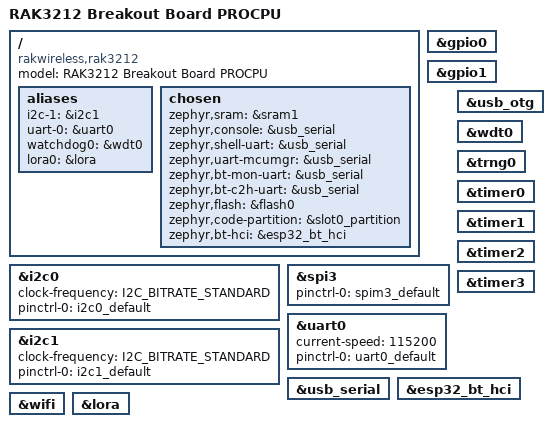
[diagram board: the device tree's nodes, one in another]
/*
 * Copyright (c) 2025 Kenneth Lu <kenneth.lu@rakwireless.com>
 * Copyright (c) 2026 JaeHwan Jin <jaehwan.jin@rakwireless.com>
 * SPDX-License-Identifier: Apache-2.0
 */

/dts-v1/;
#include <rakwireless/rak3112_procpu.dtsi>
#include <espressif/partitions_0x0_amp_16M.dtsi>
#include "rak3212-pinctrl.dtsi"

/ {
	model = "RAK3212 Breakout Board PROCPU";
	compatible = "rakwireless,rak3212";

	aliases {
		i2c-1 = &i2c1;
		uart-0 = &uart0;
		watchdog0 = &wdt0;
		lora0 = &lora;
	};

	chosen {
		zephyr,sram = &sram1;
		zephyr,console = &usb_serial;
		zephyr,shell-uart = &usb_serial;
		zephyr,uart-mcumgr = &usb_serial;
		zephyr,bt-mon-uart = &usb_serial;
		zephyr,bt-c2h-uart = &usb_serial;
		zephyr,flash = &flash0;
		zephyr,code-partition = &slot0_partition;
		zephyr,bt-hci = &esp32_bt_hci;
	};
};

&gpio0 {
	status = "okay";
};

&gpio1 {
	status = "okay";
};

&i2c0 {
	clock-frequency = <I2C_BITRATE_STANDARD>;
	pinctrl-0 = <&i2c0_default>;
	pinctrl-names = "default";
};

&i2c1 {
	clock-frequency = <I2C_BITRATE_STANDARD>;
	pinctrl-0 = <&i2c1_default>;
	pinctrl-names = "default";
};

&spi3 {
	#address-cells = <1>;
	#size-cells = <0>;
	pinctrl-0 = <&spim3_default>;
	pinctrl-names = "default";
};

&uart0 {
	status = "okay";
	current-speed = <115200>;
	pinctrl-0 = <&uart0_default>;
	pinctrl-names = "default";
};

&usb_serial {
	status = "okay";
};

zephyr_udc0: &usb_otg {
	status = "okay";
};

&wdt0 {
	status = "okay";
};

&trng0 {
	status = "okay";
};

&timer0 {
	status = "okay";
};

&timer1 {
	status = "okay";
};

&timer2 {
	status = "okay";
};

&timer3 {
	status = "okay";
};

&esp32_bt_hci {
	status = "okay";
};

&wifi {
	status = "okay";
};

&lora {
	status = "okay";
};
